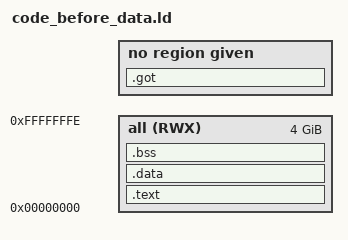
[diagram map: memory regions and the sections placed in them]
ENTRY(main)

/* Specify the memory areas */
MEMORY
{
  all                   (RWX) : ORIGIN = 0x00000000, LENGTH = 0xFFFFFFFF
}

/* Define output sections */
SECTIONS
{
  /* The startup code goes first into internal flash */
  .text :
  {
    . = ALIGN(4);
    *(.text)                 /* .text sections (code) */
    *(.text*)                /* .text* sections (code) */
    *(.rodata)               /* .rodata sections (constants, strings, etc.) */
    *(.rodata*)              /* .rodata* sections (constants, strings, etc.) */
    . = ALIGN(4);
  } > all

  .data :
  {
    . = ALIGN(4);
    *(.data)                 /* .data sections */
    *(.data*)                /* .data* sections */
    . = ALIGN(4);
  } > all

  .bss :
  {
    . = ALIGN(4);
    *(.bss)
    *(.bss*)
    . = ALIGN(4);
  } > all

  .got :
  {
    *(.got*)
  }
}

